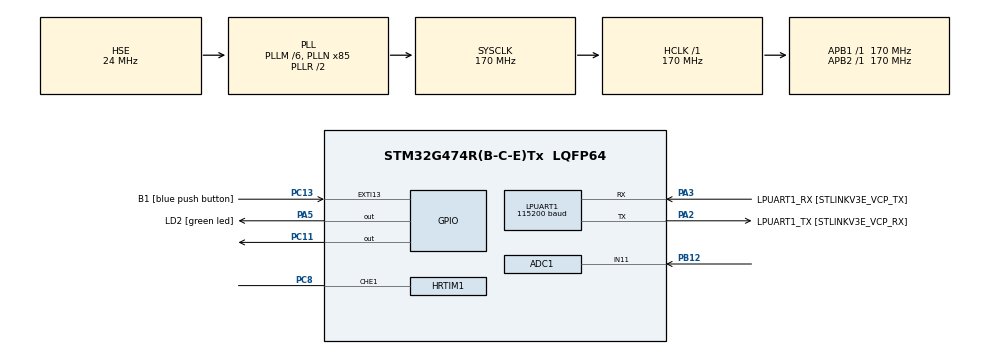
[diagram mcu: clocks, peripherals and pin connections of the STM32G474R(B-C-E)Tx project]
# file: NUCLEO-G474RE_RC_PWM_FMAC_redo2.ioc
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ADC1.Channel-0\#ChannelRegularConversion=ADC_CHANNEL_11
ADC1.DMAContinuousRequests=ENABLE
ADC1.DataAlign=ADC_DATAALIGN_LEFT
ADC1.EOCSelection=ADC_EOC_SINGLE_CONV
ADC1.ExternalTrigConv=ADC_EXTERNALTRIG_HRTIM_TRG1
ADC1.NbrOfConversionFlag=1
ADC1.Offset-0\#ChannelRegularConversion=2000
ADC1.OffsetNumber-0\#ChannelRegularConversion=ADC_OFFSET_1
ADC1.Overrun=ADC_OVR_DATA_OVERWRITTEN
ADC1.Rank-0\#ChannelRegularConversion=1
ADC1.SamplingTime-0\#ChannelRegularConversion=ADC_SAMPLETIME_6CYCLES_5
ADC1.master=1
Dma.ADC1.0.Direction=DMA_PERIPH_TO_MEMORY
Dma.ADC1.0.EventEnable=DISABLE
Dma.ADC1.0.Instance=DMA1_Channel1
Dma.ADC1.0.MemDataAlignment=DMA_MDATAALIGN_WORD
Dma.ADC1.0.MemInc=DMA_MINC_ENABLE
Dma.ADC1.0.Mode=DMA_CIRCULAR
Dma.ADC1.0.PeriphDataAlignment=DMA_PDATAALIGN_WORD
Dma.ADC1.0.PeriphInc=DMA_PINC_DISABLE
Dma.ADC1.0.Polarity=HAL_DMAMUX_REQ_GEN_RISING
Dma.ADC1.0.Priority=DMA_PRIORITY_MEDIUM
Dma.ADC1.0.RequestNumber=1
Dma.ADC1.0.SignalID=NONE
Dma.ADC1.0.SyncEnable=DISABLE
Dma.ADC1.0.SyncPolarity=HAL_DMAMUX_SYNC_NO_EVENT
Dma.ADC1.0.SyncRequestNumber=1
Dma.ADC1.0.SyncSignalID=NONE
Dma.Request0=ADC1
HRTIM1.ADCTrigger1_Source1=HRTIM_ADCTRIGGEREVENT13_TIMERE_CMP3
HRTIM1.ADCTrigger_Id1=__NULL
HRTIM1.CompareUnit1-Output_TE1=HRTIM_COMPAREUNIT_1
HRTIM1.CompareUnit2-Output_TE1=HRTIM_COMPAREUNIT_2
HRTIM1.CompareUnit3-Output_TE1=HRTIM_COMPAREUNIT_3
HRTIM1.CompareValue1-Output_TE1=10000
HRTIM1.CompareValue2-Output_TE1=15000
HRTIM1.CompareValue3-Output_TE1=25000
HRTIM1.Event_EEV1=__NULL
HRTIM1.InterruptRequests1-Output_TE1=HRTIM_TIM_IT_REP
HRTIM1.InterruptRequests2-Output_TE1=HRTIM_TIM_IT_UPD
HRTIM1.NumberADCTriggerSource1=1
HRTIM1.NumberInterruptRequests-Output_TE1=2
HRTIM1.NumberResetSource1-Output_TE1=2
HRTIM1.NumberResetTrigger-Output_TE1=1
HRTIM1.NumberSetSource1-Output_TE1=2
HRTIM1.NumberUpdateTrigger-Output_TE1=0
HRTIM1.Periode_TE=27200
HRTIM1.PreloadEnable-Output_TE1=HRTIM_PRELOAD_ENABLED
HRTIM1.PrescalerRatio_TE=HRTIM_PRESCALERRATIO_MUL8
HRTIM1.RepetitionCounter-Output_TE1=1
HRTIM1.RepetitionUpdate-Output_TE1=HRTIM_UPDATEONREPETITION_DISABLED
HRTIM1.ResetOutput1_Source1-Output_TE1=HRTIM_OUTPUTRESET_TIMCMP1
HRTIM1.ResetOutput1_Source2-Output_TE1=HRTIM_OUTPUTRESET_TIMCMP3
HRTIM1.ResetTrigger1-Output_TE1=HRTIM_TIMRESETTRIGGER_UPDATE
HRTIM1.ResetUpdate-Output_TE1=HRTIM_TIMUPDATEONRESET_ENABLED
HRTIM1.SetOutput1_Source1-Output_TE1=HRTIM_OUTPUTSET_TIMPER
HRTIM1.SetOutput1_Source2-Output_TE1=HRTIM_OUTPUTSET_TIMCMP2
LPUART1.BaudRate=115200
LPUART1.WordLength=UART_WORDLENGTH_8B
Mcu.Family=STM32G4
Mcu.Name=STM32G474R(B-C-E)Tx
Mcu.Package=LQFP64
NVIC.ADC1_2_IRQn=true\:0\:0\:false\:false\:true\:true\:true
NVIC.EXTI15_10_IRQn=true\:0\:0\:false\:false\:true\:true\:true
NVIC.HRTIM1_TIME_IRQn=true\:0\:0\:false\:false\:true\:true\:true
NVIC.PriorityGroup=NVIC_PRIORITYGROUP_4
PA13.GPIO_Label=T_SWDIO
PA13.Mode=Trace_Asynchronous_SW
PA13.Signal=SYS_JTMS-SWDIO
PA14.GPIO_Label=T_SWCLK
PA14.Mode=Trace_Asynchronous_SW
PA14.Signal=SYS_JTCK-SWCLK
PA2.GPIO_Label=LPUART1_TX [STLINKV3E_VCP_RX]
PA2.Mode=Asynchronous
PA2.Signal=LPUART1_TX
PA3.GPIO_Label=LPUART1_RX [STLINKV3E_VCP_TX]
PA3.Mode=Asynchronous
PA3.Signal=LPUART1_RX
PA5.GPIO_Label=LD2 [green led]
PA5.Signal=GPIO_Output
PB12.Mode=IN11-Single-Ended
PB12.Signal=ADC1_IN11
PB3.GPIO_Label=T_SWO
PB3.Mode=Trace_Asynchronous_SW
PB3.Signal=SYS_JTDO-SWO
PC11.Signal=GPIO_Output
PC13.GPIO_Label=B1 [blue push button]
PC13.Signal=GPXTI13
PC14-OSC32_IN.Mode=LSE-External-Oscillator
PC14-OSC32_IN.Signal=RCC_OSC32_IN
PC15-OSC32_OUT.Mode=LSE-External-Oscillator
PC15-OSC32_OUT.Signal=RCC_OSC32_OUT
PC8.GPIO_Speed_High_Default=GPIO_SPEED_FREQ_LOW
PC8.Mode=Output_TE1
PC8.Signal=HRTIM1_CHE1
PF0-OSC_IN.Mode=HSE-External-Oscillator
PF0-OSC_IN.Signal=RCC_OSC_IN
PF1-OSC_OUT.Mode=HSE-External-Oscillator
PF1-OSC_OUT.Signal=RCC_OSC_OUT
ProjectManager.HeapSize=0x200
ProjectManager.StackSize=0x400
ProjectManager.TargetToolchain=STM32CubeIDE
RCC.ADC12Freq_Value=170000000
RCC.ADC345Freq_Value=170000000
RCC.AHBFreq_Value=170000000
RCC.APB1Freq_Value=170000000
RCC.APB1TimFreq_Value=170000000
RCC.APB2Freq_Value=170000000
RCC.APB2TimFreq_Value=170000000
RCC.CortexFreq_Value=170000000
RCC.EXTERNAL_CLOCK_VALUE=12288000
RCC.HCLKFreq_Value=170000000
RCC.HSE_VALUE=24000000
RCC.HSI48_VALUE=48000000
RCC.HSI_VALUE=16000000
RCC.PLLM=RCC_PLLM_DIV6
RCC.PLLN=85
RCC.PLLSourceVirtual=RCC_PLLSOURCE_HSE
RCC.RTCClockSelection=RCC_RTCCLKSOURCE_LSE
RCC.SYSCLKFreq_VALUE=170000000
RCC.SYSCLKSource=RCC_SYSCLKSOURCE_PLLCLK
RCC.USBFreq_Value=170000000
RCC.VCOOutputFreq_Value=340000000
VP_SYS_VS_DBSignals.Mode=DisableDeadBatterySignals
board=NUCLEO-G474RE

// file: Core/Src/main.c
/* USER CODE BEGIN Header */
/**
  ******************************************************************************
  * @file           : main.c
  * @brief          : Main program body
  ******************************************************************************
  * @attention
  *
  * <h2><center>&copy; Copyright (c) 2021 STMicroelectronics.
  * All rights reserved.</center></h2>
  *
  * This software component is licensed by ST under BSD 3-Clause license,
  * the "License"; You may not use this file except in compliance with the
  * License. You may obtain a copy of the License at:
  *                        opensource.org/licenses/BSD-3-Clause
  *
  ******************************************************************************
  */
/* USER CODE END Header */
#include "main.h"

ADC_HandleTypeDef hadc1;
DMA_HandleTypeDef hdma_adc1;

HRTIM_HandleTypeDef hhrtim1;

UART_HandleTypeDef hlpuart1;

/* USER CODE BEGIN PV */

/* FMAC configuration structure */
//FMAC_FilterConfigTypeDef sFmacConfig;

///* Array of filter coefficients A (feedback coefficients) in Q1.15 format */
//static int16_t aFilterCoeffA[COEFF_VECTOR_A_SIZE] = {A1,A2,A3};
//
///* Array of filter coefficients B (feed-forward taps) in Q1.15 format */
//static int16_t aFilterCoeffB[COEFF_VECTOR_B_SIZE] = {-B0,-B1,-B2,-B3};
//
///* Array of output data to preload in Q1.15 format */
//static int16_t aOutputDataToPreload[COEFF_VECTOR_A_SIZE] = {0x0000, 0x0000, 0x0000};

/* Expected number of calculated samples */
uint16_t ExpectedCalculatedOutputSize = (uint16_t) 1;
uint32_t *Fmac_Wdata;
int16_t Fmac_output;

uint32_t tmp;

/* USER CODE END PV */

void SystemClock_Config(void);
static void MX_GPIO_Init(void);
static void MX_DMA_Init(void);
static void MX_LPUART1_UART_Init(void);
static void MX_HRTIM1_Init(void);
static void MX_ADC1_Init(void);
/* USER CODE BEGIN PFP */

static void VT_HRTIM1_Start_Output(void);

/* USER CODE END PFP */

int main(void)
{

  /* MCU Configuration--------------------------------------------------------*/

  /* Reset of all peripherals, Initializes the Flash interface and the Systick. */
  HAL_Init();

  /* Configure the system clock */
  SystemClock_Config();

  /* Initialize all configured peripherals */
  MX_GPIO_Init();
  MX_DMA_Init();
  MX_LPUART1_UART_Init();
  MX_HRTIM1_Init();
  MX_ADC1_Init();
  /* USER CODE BEGIN 2 */

//  /* Perform an ADC automatic self-calibration and enable ADC */
//  HAL_ADCEx_Calibration_Start(&hadc1, ADC_SINGLE_ENDED);
//
//  /* Start ADC and DMA */
////  Fmac_Wdata = (uint32_t *) FMAC_WDATA;
//  HAL_ADC_Start_DMA(&hadc1,&tmp,1);

	HAL_HRTIM_WaveformOutputStart(&hhrtim1, HRTIM_OUTPUT_TE1 );
	HAL_HRTIM_WaveformCountStart_IT(&hhrtim1, HRTIM_TIMERID_TIMER_E);

//  VT_HRTIM1_Start_Output();

  /* USER CODE END 2 */

  /* Infinite loop */
  /* USER CODE BEGIN WHILE */
  while (1)
  {
//	  GPIOC->BSRR = (1<<11); // start

//	  HAL_GPIO_TogglePin(GPIOA, GPIO_PIN_5);
//	  HAL_Delay(400);

//	  GPIOC->BSRR = (1<<(11+16)); // end
    /* USER CODE END WHILE */

  }
}

void SystemClock_Config(void)
{
  RCC_OscInitTypeDef RCC_OscInitStruct = {0};
  RCC_ClkInitTypeDef RCC_ClkInitStruct = {0};
  RCC_PeriphCLKInitTypeDef PeriphClkInit = {0};

  /** Configure the main internal regulator output voltage
  */
  HAL_PWREx_ControlVoltageScaling(PWR_REGULATOR_VOLTAGE_SCALE1_BOOST);
  /** Initializes the RCC Oscillators according to the specified parameters
  * in the RCC_OscInitTypeDef structure.
  */
  RCC_OscInitStruct.OscillatorType = RCC_OSCILLATORTYPE_HSE;
  RCC_OscInitStruct.HSEState = RCC_HSE_ON;
  RCC_OscInitStruct.PLL.PLLState = RCC_PLL_ON;
  RCC_OscInitStruct.PLL.PLLSource = RCC_PLLSOURCE_HSE;
  RCC_OscInitStruct.PLL.PLLM = RCC_PLLM_DIV6;
  RCC_OscInitStruct.PLL.PLLN = 85;
  RCC_OscInitStruct.PLL.PLLP = RCC_PLLP_DIV2;
  RCC_OscInitStruct.PLL.PLLQ = RCC_PLLQ_DIV2;
  RCC_OscInitStruct.PLL.PLLR = RCC_PLLR_DIV2;
  if (HAL_RCC_OscConfig(&RCC_OscInitStruct) != HAL_OK)
  {
    Error_Handler();
  }
  /** Initializes the CPU, AHB and APB buses clocks
  */
  RCC_ClkInitStruct.ClockType = RCC_CLOCKTYPE_HCLK|RCC_CLOCKTYPE_SYSCLK
                              |RCC_CLOCKTYPE_PCLK1|RCC_CLOCKTYPE_PCLK2;
  RCC_ClkInitStruct.SYSCLKSource = RCC_SYSCLKSOURCE_PLLCLK;
  RCC_ClkInitStruct.AHBCLKDivider = RCC_SYSCLK_DIV1;
  RCC_ClkInitStruct.APB1CLKDivider = RCC_HCLK_DIV1;
  RCC_ClkInitStruct.APB2CLKDivider = RCC_HCLK_DIV1;

  if (HAL_RCC_ClockConfig(&RCC_ClkInitStruct, FLASH_LATENCY_4) != HAL_OK)
  {
    Error_Handler();
  }
  /** Initializes the peripherals clocks
  */
  PeriphClkInit.PeriphClockSelection = RCC_PERIPHCLK_LPUART1|RCC_PERIPHCLK_ADC12;
  PeriphClkInit.Lpuart1ClockSelection = RCC_LPUART1CLKSOURCE_PCLK1;
  PeriphClkInit.Adc12ClockSelection = RCC_ADC12CLKSOURCE_SYSCLK;
  if (HAL_RCCEx_PeriphCLKConfig(&PeriphClkInit) != HAL_OK)
  {
    Error_Handler();
  }
}

static void MX_ADC1_Init(void)
{

  ADC_MultiModeTypeDef multimode = {0};
  ADC_ChannelConfTypeDef sConfig = {0};

  /** Common config
  */
  hadc1.Instance = ADC1;
  hadc1.Init.ClockPrescaler = ADC_CLOCK_SYNC_PCLK_DIV4;
  hadc1.Init.Resolution = ADC_RESOLUTION_12B;
  hadc1.Init.DataAlign = ADC_DATAALIGN_LEFT;
  hadc1.Init.GainCompensation = 0;
  hadc1.Init.ScanConvMode = ADC_SCAN_DISABLE;
  hadc1.Init.EOCSelection = ADC_EOC_SINGLE_CONV;
  hadc1.Init.LowPowerAutoWait = DISABLE;
  hadc1.Init.ContinuousConvMode = DISABLE;
  hadc1.Init.NbrOfConversion = 1;
  hadc1.Init.DiscontinuousConvMode = DISABLE;
  hadc1.Init.ExternalTrigConv = ADC_EXTERNALTRIG_HRTIM_TRG1;
  hadc1.Init.ExternalTrigConvEdge = ADC_EXTERNALTRIGCONVEDGE_RISING;
  hadc1.Init.DMAContinuousRequests = ENABLE;
  hadc1.Init.Overrun = ADC_OVR_DATA_OVERWRITTEN;
  hadc1.Init.OversamplingMode = DISABLE;
  if (HAL_ADC_Init(&hadc1) != HAL_OK)
  {
    Error_Handler();
  }
  /** Configure the ADC multi-mode
  */
  multimode.Mode = ADC_MODE_INDEPENDENT;
  if (HAL_ADCEx_MultiModeConfigChannel(&hadc1, &multimode) != HAL_OK)
  {
    Error_Handler();
  }
  /** Configure Regular Channel
  */
  sConfig.Channel = ADC_CHANNEL_11;
  sConfig.Rank = ADC_REGULAR_RANK_1;
  sConfig.SamplingTime = ADC_SAMPLETIME_6CYCLES_5;
  sConfig.SingleDiff = ADC_SINGLE_ENDED;
  sConfig.OffsetNumber = ADC_OFFSET_1;
  sConfig.Offset = 2000;
  sConfig.OffsetSign = ADC_OFFSET_SIGN_NEGATIVE;
  sConfig.OffsetSaturation = DISABLE;
  if (HAL_ADC_ConfigChannel(&hadc1, &sConfig) != HAL_OK)
  {
    Error_Handler();
  }
  /* USER CODE BEGIN ADC1_Init 2 */

  /* CubeMX enables DMA interrupt even if not configured */
  HAL_NVIC_DisableIRQ(DMA1_Channel1_IRQn);

  /* USER CODE END ADC1_Init 2 */

}

static void MX_HRTIM1_Init(void)
{

  HRTIM_TimeBaseCfgTypeDef pTimeBaseCfg = {0};
  HRTIM_TimerCtlTypeDef pTimerCtl = {0};
  HRTIM_TimerCfgTypeDef pTimerCfg = {0};
  HRTIM_CompareCfgTypeDef pCompareCfg = {0};
  HRTIM_OutputCfgTypeDef pOutputCfg = {0};

  hhrtim1.Instance = HRTIM1;
  hhrtim1.Init.HRTIMInterruptResquests = HRTIM_IT_NONE;
  hhrtim1.Init.SyncOptions = HRTIM_SYNCOPTION_NONE;
  if (HAL_HRTIM_Init(&hhrtim1) != HAL_OK)
  {
    Error_Handler();
  }
  if (HAL_HRTIM_DLLCalibrationStart(&hhrtim1, HRTIM_CALIBRATIONRATE_3) != HAL_OK)
  {
    Error_Handler();
  }
  if (HAL_HRTIM_PollForDLLCalibration(&hhrtim1, 10) != HAL_OK)
  {
    Error_Handler();
  }
  pTimeBaseCfg.Period = 27200;
  pTimeBaseCfg.RepetitionCounter = 1;
  pTimeBaseCfg.PrescalerRatio = HRTIM_PRESCALERRATIO_MUL8;
  pTimeBaseCfg.Mode = HRTIM_MODE_CONTINUOUS;
  if (HAL_HRTIM_TimeBaseConfig(&hhrtim1, HRTIM_TIMERINDEX_TIMER_E, &pTimeBaseCfg) != HAL_OK)
  {
    Error_Handler();
  }
  pTimerCtl.UpDownMode = HRTIM_TIMERUPDOWNMODE_UP;
  pTimerCtl.TrigHalf = HRTIM_TIMERTRIGHALF_DISABLED;
  pTimerCtl.GreaterCMP3 = HRTIM_TIMERGTCMP3_EQUAL;
  pTimerCtl.GreaterCMP1 = HRTIM_TIMERGTCMP1_EQUAL;
  pTimerCtl.DualChannelDacEnable = HRTIM_TIMER_DCDE_DISABLED;
  if (HAL_HRTIM_WaveformTimerControl(&hhrtim1, HRTIM_TIMERINDEX_TIMER_E, &pTimerCtl) != HAL_OK)
  {
    Error_Handler();
  }
  pTimerCfg.InterruptRequests = HRTIM_MASTER_IT_NONE;
  pTimerCfg.DMARequests = HRTIM_TIM_DMA_NONE;
  pTimerCfg.DMASrcAddress = 0x0000;
  pTimerCfg.DMADstAddress = 0x0000;
  pTimerCfg.DMASize = 0x1;
  pTimerCfg.HalfModeEnable = HRTIM_HALFMODE_DISABLED;
  pTimerCfg.InterleavedMode = HRTIM_INTERLEAVED_MODE_DISABLED;
  pTimerCfg.StartOnSync = HRTIM_SYNCSTART_DISABLED;
  pTimerCfg.ResetOnSync = HRTIM_SYNCRESET_DISABLED;
  pTimerCfg.DACSynchro = HRTIM_DACSYNC_NONE;
  pTimerCfg.PreloadEnable = HRTIM_PRELOAD_ENABLED;
  pTimerCfg.UpdateGating = HRTIM_UPDATEGATING_INDEPENDENT;
  pTimerCfg.BurstMode = HRTIM_TIMERBURSTMODE_MAINTAINCLOCK;
  pTimerCfg.RepetitionUpdate = HRTIM_UPDATEONREPETITION_DISABLED;
  pTimerCfg.PushPull = HRTIM_TIMPUSHPULLMODE_DISABLED;
  pTimerCfg.FaultEnable = HRTIM_TIMFAULTENABLE_NONE;
  pTimerCfg.FaultLock = HRTIM_TIMFAULTLOCK_READWRITE;
  pTimerCfg.DeadTimeInsertion = HRTIM_TIMDEADTIMEINSERTION_DISABLED;
  pTimerCfg.DelayedProtectionMode = HRTIM_TIMER_D_E_DELAYEDPROTECTION_DISABLED;
  pTimerCfg.UpdateTrigger = HRTIM_TIMUPDATETRIGGER_NONE;
  pTimerCfg.ResetTrigger = HRTIM_TIMRESETTRIGGER_UPDATE;
  pTimerCfg.ResetUpdate = HRTIM_TIMUPDATEONRESET_ENABLED;
  pTimerCfg.ReSyncUpdate = HRTIM_TIMERESYNC_UPDATE_UNCONDITIONAL;
  if (HAL_HRTIM_WaveformTimerConfig(&hhrtim1, HRTIM_TIMERINDEX_TIMER_E, &pTimerCfg) != HAL_OK)
  {
    Error_Handler();
  }
  pCompareCfg.CompareValue = 10000;
  if (HAL_HRTIM_WaveformCompareConfig(&hhrtim1, HRTIM_TIMERINDEX_TIMER_E, HRTIM_COMPAREUNIT_1, &pCompareCfg) != HAL_OK)
  {
    Error_Handler();
  }
  pCompareCfg.CompareValue = 15000;
  pCompareCfg.AutoDelayedMode = HRTIM_AUTODELAYEDMODE_REGULAR;
  pCompareCfg.AutoDelayedTimeout = 0x0000;

  if (HAL_HRTIM_WaveformCompareConfig(&hhrtim1, HRTIM_TIMERINDEX_TIMER_E, HRTIM_COMPAREUNIT_2, &pCompareCfg) != HAL_OK)
  {
    Error_Handler();
  }
  pCompareCfg.CompareValue = 25000;
  if (HAL_HRTIM_WaveformCompareConfig(&hhrtim1, HRTIM_TIMERINDEX_TIMER_E, HRTIM_COMPAREUNIT_3, &pCompareCfg) != HAL_OK)
  {
    Error_Handler();
  }
  pOutputCfg.Polarity = HRTIM_OUTPUTPOLARITY_HIGH;
  pOutputCfg.SetSource = HRTIM_OUTPUTSET_TIMPER|HRTIM_OUTPUTSET_TIMCMP2;
  pOutputCfg.ResetSource = HRTIM_OUTPUTRESET_TIMCMP1|HRTIM_OUTPUTRESET_TIMCMP3;
  pOutputCfg.IdleMode = HRTIM_OUTPUTIDLEMODE_NONE;
  pOutputCfg.IdleLevel = HRTIM_OUTPUTIDLELEVEL_INACTIVE;
  pOutputCfg.FaultLevel = HRTIM_OUTPUTFAULTLEVEL_NONE;
  pOutputCfg.ChopperModeEnable = HRTIM_OUTPUTCHOPPERMODE_DISABLED;
  pOutputCfg.BurstModeEntryDelayed = HRTIM_OUTPUTBURSTMODEENTRY_REGULAR;
  if (HAL_HRTIM_WaveformOutputConfig(&hhrtim1, HRTIM_TIMERINDEX_TIMER_E, HRTIM_OUTPUT_TE1, &pOutputCfg) != HAL_OK)
  {
    Error_Handler();
  }
  HAL_HRTIM_MspPostInit(&hhrtim1);

}

static void MX_LPUART1_UART_Init(void)
{

  hlpuart1.Instance = LPUART1;
  hlpuart1.Init.BaudRate = 115200;
  hlpuart1.Init.WordLength = UART_WORDLENGTH_8B;
  hlpuart1.Init.StopBits = UART_STOPBITS_1;
  hlpuart1.Init.Parity = UART_PARITY_NONE;
  hlpuart1.Init.Mode = UART_MODE_TX_RX;
  hlpuart1.Init.HwFlowCtl = UART_HWCONTROL_NONE;
  hlpuart1.Init.OneBitSampling = UART_ONE_BIT_SAMPLE_DISABLE;
  hlpuart1.Init.ClockPrescaler = UART_PRESCALER_DIV1;
  hlpuart1.AdvancedInit.AdvFeatureInit = UART_ADVFEATURE_NO_INIT;
  if (HAL_UART_Init(&hlpuart1) != HAL_OK)
  {
    Error_Handler();
  }
  if (HAL_UARTEx_SetTxFifoThreshold(&hlpuart1, UART_TXFIFO_THRESHOLD_1_8) != HAL_OK)
  {
    Error_Handler();
  }
  if (HAL_UARTEx_SetRxFifoThreshold(&hlpuart1, UART_RXFIFO_THRESHOLD_1_8) != HAL_OK)
  {
    Error_Handler();
  }
  if (HAL_UARTEx_DisableFifoMode(&hlpuart1) != HAL_OK)
  {
    Error_Handler();
  }

}

static void MX_DMA_Init(void)
{

  /* DMA controller clock enable */
  __HAL_RCC_DMAMUX1_CLK_ENABLE();
  __HAL_RCC_DMA1_CLK_ENABLE();

}

static void MX_GPIO_Init(void)
{
  GPIO_InitTypeDef GPIO_InitStruct = {0};

  /* GPIO Ports Clock Enable */
  __HAL_RCC_GPIOC_CLK_ENABLE();
  __HAL_RCC_GPIOF_CLK_ENABLE();
  __HAL_RCC_GPIOA_CLK_ENABLE();
  __HAL_RCC_GPIOB_CLK_ENABLE();

  /*Configure GPIO pin Output Level */
  HAL_GPIO_WritePin(LD2_GPIO_Port, LD2_Pin, GPIO_PIN_RESET);

  /*Configure GPIO pin Output Level */
  HAL_GPIO_WritePin(GPIOC, GPIO_PIN_11, GPIO_PIN_RESET);

  /*Configure GPIO pin : B1_Pin */
  GPIO_InitStruct.Pin = B1_Pin;
  GPIO_InitStruct.Mode = GPIO_MODE_IT_RISING;
  GPIO_InitStruct.Pull = GPIO_NOPULL;
  HAL_GPIO_Init(B1_GPIO_Port, &GPIO_InitStruct);

  /*Configure GPIO pin : LD2_Pin */
  GPIO_InitStruct.Pin = LD2_Pin;
  GPIO_InitStruct.Mode = GPIO_MODE_OUTPUT_PP;
  GPIO_InitStruct.Pull = GPIO_NOPULL;
  GPIO_InitStruct.Speed = GPIO_SPEED_FREQ_LOW;
  HAL_GPIO_Init(LD2_GPIO_Port, &GPIO_InitStruct);

  /*Configure GPIO pin : PC11 */
  GPIO_InitStruct.Pin = GPIO_PIN_11;
  GPIO_InitStruct.Mode = GPIO_MODE_OUTPUT_PP;
  GPIO_InitStruct.Pull = GPIO_NOPULL;
  GPIO_InitStruct.Speed = GPIO_SPEED_FREQ_LOW;
  HAL_GPIO_Init(GPIOC, &GPIO_InitStruct);

  /* EXTI interrupt init*/
  HAL_NVIC_SetPriority(EXTI15_10_IRQn, 0, 0);
  HAL_NVIC_EnableIRQ(EXTI15_10_IRQn);

}

/* USER CODE BEGIN 4 */

static void VT_HRTIM1_Start_Output(void)
{

	HAL_HRTIM_WaveformOutputStart(&hhrtim1, HRTIM_OUTPUT_TE1 );
	HAL_HRTIM_WaveformCountStart_IT(&hhrtim1, HRTIM_TIMERID_TIMER_E);

}

/* USER CODE END 4 */

void Error_Handler(void)
{
  __disable_irq();
  while (1)
  {
  }
}

/************************ (C) COPYRIGHT STMicroelectronics *****END OF FILE****/
